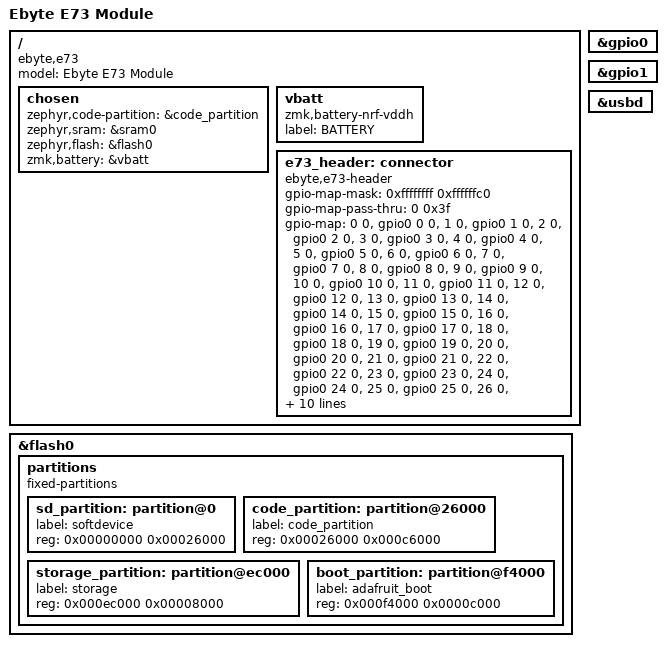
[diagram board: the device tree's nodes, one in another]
/*
 * Copyright (c) 2024
 * SPDX-License-Identifier: MIT
 */

/dts-v1/;
#include <nordic/nrf52840_qiaa.dtsi>

/ {
    model = "Ebyte E73 Module";
    compatible = "ebyte,e73";

    chosen {
        zephyr,code-partition = &code_partition;
        zephyr,sram = &sram0;
        zephyr,flash = &flash0;
        zmk,battery = &vbatt;
    };

    vbatt: vbatt {
        compatible = "zmk,battery-nrf-vddh";
        label = "BATTERY";
    };

    e73_header: connector {
        compatible = "ebyte,e73-header";
        #gpio-cells = <2>;
        gpio-map-mask = <0xffffffff 0xffffffc0>;
        gpio-map-pass-thru = <0 0x3f>;
        gpio-map = <0 0 &gpio0 0 0>, <1 0 &gpio0 1 0>,
                   <2 0 &gpio0 2 0>, <3 0 &gpio0 3 0>,
                   <4 0 &gpio0 4 0>, <5 0 &gpio0 5 0>,
                   <6 0 &gpio0 6 0>, <7 0 &gpio0 7 0>,
                   <8 0 &gpio0 8 0>, <9 0 &gpio0 9 0>,
                   <10 0 &gpio0 10 0>, <11 0 &gpio0 11 0>,
                   <12 0 &gpio0 12 0>, <13 0 &gpio0 13 0>,
                   <14 0 &gpio0 14 0>, <15 0 &gpio0 15 0>,
                   <16 0 &gpio0 16 0>, <17 0 &gpio0 17 0>,
                   <18 0 &gpio0 18 0>, <19 0 &gpio0 19 0>,
                   <20 0 &gpio0 20 0>, <21 0 &gpio0 21 0>,
                   <22 0 &gpio0 22 0>, <23 0 &gpio0 23 0>,
                   <24 0 &gpio0 24 0>, <25 0 &gpio0 25 0>,
                   <26 0 &gpio0 26 0>, <27 0 &gpio0 27 0>,
                   <28 0 &gpio0 28 0>, <29 0 &gpio0 29 0>,
                   <30 0 &gpio0 30 0>, <31 0 &gpio0 31 0>,
                   <32 0 &gpio1 0 0>, <33 0 &gpio1 1 0>,
                   <34 0 &gpio1 2 0>, <35 0 &gpio1 3 0>,
                   <36 0 &gpio1 4 0>, <37 0 &gpio1 5 0>,
                   <38 0 &gpio1 6 0>, <39 0 &gpio1 7 0>,
                   <40 0 &gpio1 8 0>, <41 0 &gpio1 9 0>,
                   <42 0 &gpio1 10 0>, <43 0 &gpio1 11 0>,
                   <44 0 &gpio1 12 0>, <45 0 &gpio1 13 0>,
                   <46 0 &gpio1 14 0>, <47 0 &gpio1 15 0>;
    };
};

&flash0 {
    /*
     * For more information, see:
     * http://docs.zephyrproject.org/latest/devices/dts/flash_partitions.html
     */
    partitions {
        compatible = "fixed-partitions";
        #address-cells = <1>;
        #size-cells = <1>;

        sd_partition: partition@0 {
            label = "softdevice";
            reg = <0x00000000 0x00026000>;
        };
        code_partition: partition@26000 {
            label = "code_partition";
            reg = <0x00026000 0x000c6000>;
        };

        /*
         * The flash starting at 0x000ec000 and ending at
         * 0x000f3fff is reserved for use by the application.
         */
        storage_partition: partition@ec000 {
            label = "storage";
            reg = <0x000ec000 0x00008000>;
        };

        boot_partition: partition@f4000 {
            label = "adafruit_boot";
            reg = <0x000f4000 0x0000c000>;
        };
    };
};

&gpio0 {
    status = "okay";
};

&gpio1 {
    status = "okay";
};

&usbd {
    status = "okay";
};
